# ESP32S31_RADIO register map
Vendor: Espressif; Series: ESP32-S31; File version: 3.52
Registers are 32-bit, read-write, no defined reset value unless marked. A register's access mark holds for its fields unless they carry their own. Offsets are from the block's base; [hi:lo] are bit positions; {n}, {i} and the like mark numbered series.

## WIFI_MAC_HE_INIT_SUFFIX — Complete hardware-visible hal_he_init suffix after dbg_read_tx_power, including all reached leaves. It contains 163 ordered writes/RMWs plus the two multi-BSSID guard reads.
Base 0x20104020
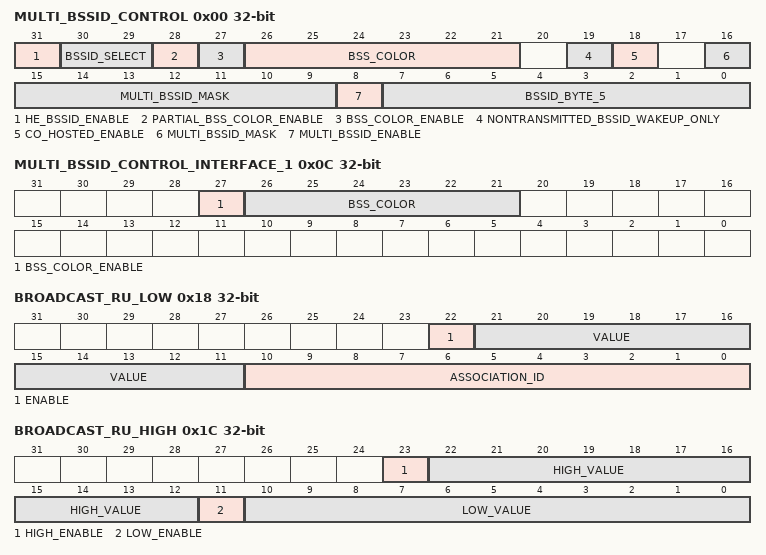
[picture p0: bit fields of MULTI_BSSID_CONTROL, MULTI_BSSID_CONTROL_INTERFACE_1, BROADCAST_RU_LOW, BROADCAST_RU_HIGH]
0x00 MULTI_BSSID_CONTROL — Project-assigned name. WDEV_HE_BSSID0_CONF. Complete dbg_read_rx_misc names the BSSID byte, multi-BSSID, co-hosted and HE BSS-color fields. Complete hal_he_bssid_init sets HE_BSSID_ENABLE and clears BSSID_SELECT for interface zero before its power-save tail; open associated-STA HIL read those values as one and zero. Complete initialization, clear and co-hosted leaves independently update the low fields.
  [31] HE_BSSID_ENABLE — Project-assigned name. Complete hal_he_bssid_init sets bit 31 for interface zero before clearing BSSID_SELECT; hal_he_bssid_deinit clears it, and dbg_read_rx_misc names it HE_BSSID_EN.
  [30:29] BSSID_SELECT — Project-assigned name. Complete hal_he_bssid_init clears both selector bits for interface zero after enabling HE BSSID matching; dbg_read_rx_misc names the two-bit field HE_BSSID_IDX.
  [28] PARTIAL_BSS_COLOR_ENABLE — Project-assigned name.
  [27] BSS_COLOR_ENABLE — Project-assigned name.
  [26:21] BSS_COLOR — Project-assigned name.
  [19] NONTRANSMITTED_BSSID_WAKEUP_ONLY — Project-assigned name.
  [18] CO_HOSTED_ENABLE — Project-assigned name.
  [16:9] MULTI_BSSID_MASK — Project-assigned name.
  [8] MULTI_BSSID_ENABLE — Project-assigned name.
  [7:0] BSSID_BYTE_5 — Project-assigned name.
0x08 MULTI_BSSID_HIGH — Project-assigned name. Complete clear leaf clears bits 23:16.
  [23:16] BITS_16_23_OPAQUE — Opaque: meaning not established.
0x0C MULTI_BSSID_CONTROL_INTERFACE_1 ro — Project-assigned name. When libpp[hal_mac_ctl.o]::hal_he_get_bss_color selects interface one, BSS_COLOR_ENABLE gates the returned six-bit BSS color from this word. Other fields remain unnamed.
  [27] BSS_COLOR_ENABLE — Project-assigned name.
  [26:21] BSS_COLOR — Project-assigned name.
0x18 BROADCAST_RU_LOW — Project-assigned name. Complete hal_he_set_bcast_ru(0x7fd,0,0) sets enable bit 22 then replaces the adjacent eleven-bit value.
  [22] ENABLE — Project-assigned name.
  [21:11] VALUE — Project-assigned name.
  [10:0] ASSOCIATION_ID — Project-assigned name. Interface-zero AID copied into the low eleven bits by the complete association leaf.
0x1C BROADCAST_RU_HIGH — Project-assigned name. Complete hal_he_set_bcast_ru independently sets bit 11, replaces bits 10:0, sets bit 23 and replaces bits 22:12.
  [23] HIGH_ENABLE — Project-assigned name.
  [22:12] HIGH_VALUE — Project-assigned name.
  [11] LOW_ENABLE — Project-assigned name.
  [10:0] LOW_VALUE — Project-assigned name.
0xEC DUMP_COMPLETE_HESIGB — Project-assigned name. Complete disable leaf clears bit zero.
  [0] ENABLE — Project-assigned name.
0x298 TX_MODE_CONTROL — Project-assigned name. Parent replaces bits 31:30 with one after the HE scratch clear.
  [31:30] BEACON_FILTER_FRAME_CRC_STATE — Project-assigned name.
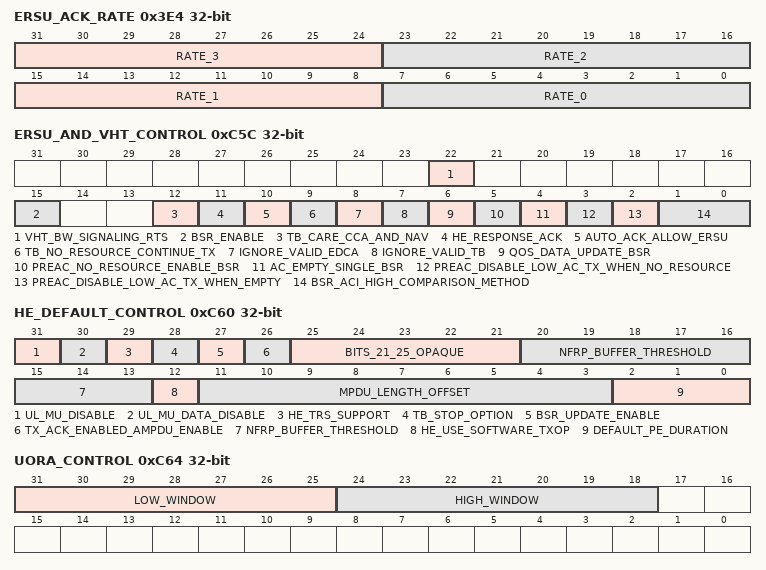
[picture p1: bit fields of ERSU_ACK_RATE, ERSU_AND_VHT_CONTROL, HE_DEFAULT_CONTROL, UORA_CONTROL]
0x3E4 ERSU_ACK_RATE — Project-assigned name. Complete libpp[hal_mac_ctl.o]::hal_he_set_ersu_ack_rate writes the same byte through four separate fresh-read RMWs: argument zero selects 0x80 and nonzero selects 0xa0. Complete libpp[trc.o]::trc_set_bf_report_rate calls this leaf after publishing BF_REPORT_RATE, selecting 0xa0 only for its low-link-metric DCM plus ER-SU branch.
  [31:24] RATE_3 — Project-assigned name. Fourth byte written by libpp[hal_mac_ctl.o]::hal_he_set_ersu_ack_rate.
  [23:16] RATE_2 — Project-assigned name. Third byte written by libpp[hal_mac_ctl.o]::hal_he_set_ersu_ack_rate.
  [15:8] RATE_1 — Project-assigned name. Second byte written by libpp[hal_mac_ctl.o]::hal_he_set_ersu_ack_rate.
  [7:0] RATE_0 — Project-assigned name. First byte written by libpp[hal_mac_ctl.o]::hal_he_set_ersu_ack_rate.
0xC5C ERSU_AND_VHT_CONTROL — Project-assigned name. Complete dbg_read_bsr_info names bits 8:2 and the comparison method. Complete dbg_read_rx_misc names bits 9:11. Complete dbg_tb_ignore_cca_enable proves that bit 12 set means TB respects CCA and NAV, while clearing it enables the debug ignore mode. Complete hal_he_bsr_init initializes the BSR comparison method and control bits. The HE Operation ER-SU-Disable bit at complete-IE byte five bit zero controls bit 10 through complete libpp[hal_mac_ctl.o]::hal_he_set_ersu. VHT bandwidth-signaling RTS disable later clears bit 22.
  [22] VHT_BW_SIGNALING_RTS — Project-assigned name.
  [15] BSR_ENABLE — Project-assigned name. Complete hal_he_bsr_init sets this bit; complete hal_he_bsr_ctrl controls it.
  [12] TB_CARE_CCA_AND_NAV — Project-assigned name. Complete dbg_tb_ignore_cca_enable clears this bit and logs "tb ignore CCA and NAV" for a nonzero argument; it sets the bit and logs "tb care CCA and NAV" for zero.
  [11] HE_RESPONSE_ACK — Project-assigned name.
  [10] AUTO_ACK_ALLOW_ERSU — Project-assigned name. Complete dbg_read_rx_misc names the bit AUTOACK_ALLOW_ERSU. Complete libpp[hal_mac_ctl.o]::hal_he_set_ersu clears it for a nonzero HE Operation ER-SU argument and sets it for zero; the PAC preserves that counterintuitive instruction-exact polarity.
  [9] TB_NO_RESOURCE_CONTINUE_TX — Project-assigned name.
  [8] IGNORE_VALID_EDCA — Project-assigned name.
  [7] IGNORE_VALID_TB — Project-assigned name.
  [6] QOS_DATA_UPDATE_BSR — Project-assigned name.
  [5] PREAC_NO_RESOURCE_ENABLE_BSR — Project-assigned name. Complete dbg_read_bsr_info names this PREAC_NORES_ENA_BSR.
  [4] AC_EMPTY_SINGLE_BSR — Project-assigned name.
  [3] PREAC_DISABLE_LOW_AC_TX_WHEN_NO_RESOURCE — Project-assigned name. Complete dbg_read_bsr_info names this PREAC_DIS_LOWACTX NORES.
  [2] PREAC_DISABLE_LOW_AC_TX_WHEN_EMPTY — Project-assigned name. Complete dbg_read_bsr_info names this PREAC_DIS_LOWACTX EMPTY.
  [1:0] BSR_ACI_HIGH_COMPARISON_METHOD — Project-assigned name. Complete init replaces the field with one; complete get/set leaves prove its width; complete dbg_read_bsr_info names the field CMP_BSR_METHOD.
0xC60 HE_DEFAULT_CONTROL — Project-assigned name. Canonical WDEVAXOPTIONS2 register. Parent replaces MPDU_LENGTH_OFFSET bits 11:3 with 0x17c after minimum-power setup. Complete hal_he_set_default_pe replaces bits 2:0 with the low three bits of its argument. Complete dbg_read_rx_misc names bits 12:20 and 28:31; complete dbg_read_bsr_info names bits 26:27. Complete hal_he_init and later HE OMC handling independently update UL-MU disable bits 30:31.
  [31] UL_MU_DISABLE — Project-assigned name. HE Operating Mode Control UL MU Disable copied from HT-Control bit 11 by wifi_htc_omc_txcb.
  [30] UL_MU_DATA_DISABLE — Project-assigned name. HE Operating Mode Control UL MU Data Disable copied from HT-Control bit 17 by wifi_htc_omc_txcb.
  [29] HE_TRS_SUPPORT — Project-assigned name.
  [28] TB_STOP_OPTION — Project-assigned name.
  [27] BSR_UPDATE_ENABLE — Project-assigned name. Complete hal_he_bsr_init sets bit 27 through a separate fresh-read RMW; complete dbg_read_bsr_info names it BSR_UPDATE_EN.
  [26] TX_ACK_ENABLED_AMPDU_ENABLE — Project-assigned name. Complete dbg_read_bsr_info names bit 26 TX_ACK_ENABLED_AMPDU_EN.
  [25:21] BITS_21_25_OPAQUE — Opaque: meaning not established.
  [20:13] NFRP_BUFFER_THRESHOLD — Project-assigned name.
  [12] HE_USE_SOFTWARE_TXOP — Project-assigned name.
  [11:3] MPDU_LENGTH_OFFSET — Project-assigned name.
  [2:0] DEFAULT_PE_DURATION — Project-assigned name. Three-bit Default Packet Extension duration copied from HE Operation Parameters byte zero.
0xC64 UORA_CONTROL — Project-assigned name. Complete hal_he_set_uora_parameter with byte 0x2b writes 0x07 into bits 31:25 then 0x1f into bits 24:18.
  [31:25] LOW_WINDOW — Project-assigned name.
  [24:18] HIGH_WINDOW — Project-assigned name.
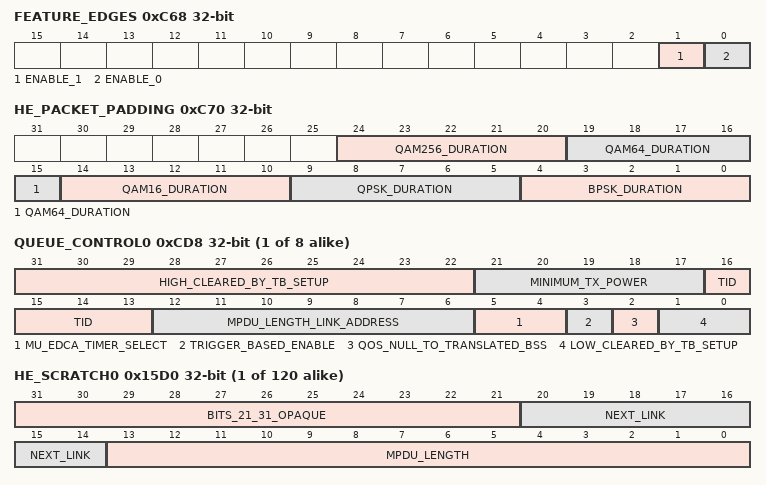
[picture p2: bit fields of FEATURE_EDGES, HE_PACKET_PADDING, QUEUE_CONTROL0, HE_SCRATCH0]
0xC68 FEATURE_EDGES — Project-assigned name. Parent sets bit one then bit zero through separate fresh-read RMWs.
  [1] ENABLE_1 — Project-assigned name.
  [0] ENABLE_0 — Project-assigned name.
0xC70 HE_PACKET_PADDING — Project-assigned name. Five five-bit NOMINAL_PKT_PADDING values decoded by complete dbg_read_rx_misc and derived from the peer HE capability.
  [24:20] QAM256_DURATION — Project-assigned name.
  [19:15] QAM64_DURATION — Project-assigned name.
  [14:10] QAM16_DURATION — Project-assigned name.
  [9:5] QPSK_DURATION — Project-assigned name.
  [4:0] BPSK_DURATION — Project-assigned name.
0xCA0 SHARED_ENABLE_CONTROL — Project-assigned name. Parent sets bit 31.
  [31] BIT_31_OPAQUE — Opaque: meaning not established.
{0xCA8+0x10*i} QOS_NULL_TRANSLATION_CONTROL{i} (i=0..2) — Project-assigned name. Three control words updated in address order by complete hal_he_set_hw_qos_null_ra_to_trans. The public leaf sets or clears bit two in every word; the hardware identities of the three profiles remain unknown.
  [2] QOS_NULL_RA_TO_TRANSLATED_BSS — Project-assigned name.
{0xCD8+0x10*i} QUEUE_CONTROL{i} (i=0..7) — Project-assigned name. Canonical WDEVTXQ_CONF1. Eight physical queue words are addressed in reverse logical order: physical array index seven is logical queue zero. Complete multi-BSSID clear independently clears bit two. Complete blob and ROM libpp[hal_mac_tx.o]::mac_tx_set_tb and rom[]::mac_tx_set_tb construct the logical-queue-zero-through-three word from only the preserved bit two, TB_ENA, logical queue as MU-EDCA selection, first MPDU-link index and frame TID; all other bits are cleared. The legacy PPDU formatter clears bit 3 of physical entries four through seven, which is the same TB_ENA field rather than an independent PPDU-control register. An open ordinary-SU HE pre-port baseline read all eight logical queues with TB_ENA=0 and the decoded TID, MU-EDCA selection, MPDU-length-link and minimum-power fields zero; Trigger/TB hardware counters also remained zero.
  [31:22] HIGH_CLEARED_BY_TB_SETUP — Project-assigned name. Bits 31:22 are cleared by complete libpp[hal_mac_tx.o]::mac_tx_set_tb/rom[]::mac_tx_set_tb.
  [21:17] MINIMUM_TX_POWER — Project-assigned name. Cleared by complete libpp[hal_mac_tx.o]::mac_tx_set_tb/rom[]::mac_tx_set_tb; the earlier debug decoder supplies the field name.
  [16:13] TID — Project-assigned name. Low four bits of the QoS descriptor state selected by complete libpp[hal_mac_tx.o]::mac_tx_set_tb/rom[]::mac_tx_set_tb.
  [12:6] MPDU_LENGTH_LINK_ADDRESS — Project-assigned name. First seven-bit link returned by complete libpp[hal_mac_tx.o]::mac_tx_set_mplen.
  [5:4] MU_EDCA_TIMER_SELECT — Project-assigned name. Complete libpp[hal_mac_tx.o]::mac_tx_set_tb/rom[]::mac_tx_set_tb copies the two-bit logical queue number here.
  [3] TRIGGER_BASED_ENABLE — Project-assigned name. Complete dbg_read_txq_conf1 names bit 3 TB_ENA; complete libpp[hal_mac_tx.o]::mac_tx_set_tb/rom[]::mac_tx_set_tb sets it.
  [2] QOS_NULL_TO_TRANSLATED_BSS — Project-assigned name. The sole pre-existing bit preserved by complete libpp[hal_mac_tx.o]::mac_tx_set_tb/rom[]::mac_tx_set_tb.
  [1:0] LOW_CLEARED_BY_TB_SETUP — Project-assigned name. Bits zero and one are cleared by complete libpp[hal_mac_tx.o]::mac_tx_set_tb/rom[]::mac_tx_set_tb.
{0x15D0+4i} HE_SCRATCH{i} (i=0..119) — Project-assigned name. Parent clears 120 consecutive words from 0x201055f0 through 0x201057cc. Complete dbg_read_tx_mplen reads the same aperture as the hardware TX MPDU-length link table and names bits 13:0 MPDU_LEN and bits 20:14 NEXT. Complete libpp[hal_mac_tx.o]::mac_tx_set_mplen preserves bits 31:21, writes the fourteen-bit DMA metadata length (plus four when metadata word one bit 28 is set), and links contiguous allocated entries; the terminal entry uses NEXT=0x7f.
  [31:21] BITS_21_31_OPAQUE — Opaque: meaning not established.
  [20:14] NEXT_LINK — Project-assigned name.
  [13:0] MPDU_LENGTH — Project-assigned name.
